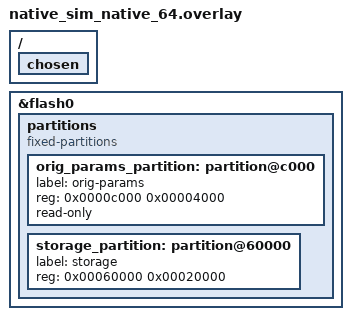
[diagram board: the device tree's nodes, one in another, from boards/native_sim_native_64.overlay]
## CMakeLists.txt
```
# SPDX-License-Identifier: Apache-2.0
# Wallfree-Anwendung fuer die Steuerung (nur bauen, nicht flashen) und fuer
# native_sim (Ende-zu-Ende-Test auf dem PC, docs/implementierung.md)
cmake_minimum_required(VERSION 3.20.0)
list(APPEND BOARD_ROOT ${CMAKE_CURRENT_SOURCE_DIR}/..)
list(APPEND ZEPHYR_EXTRA_MODULES ${CMAKE_CURRENT_SOURCE_DIR}/..)
# SOLL-BOOT-35: Anhang mit Laenge und CRC32 an zephyr.bin; nur dieses Abbild flashen
# (zephyr.hex/.elf haben ihn nicht, die Firmware verweigert dann das Laden). Vor
# find_package, weil Zephyr die Liste dort schon auswertet; fuer native_sim gibt es keine
# zephyr.bin, das Skript tut dann nichts.
set_property(GLOBAL APPEND PROPERTY extra_post_build_commands
  COMMAND python3 -I ${CMAKE_CURRENT_SOURCE_DIR}/../scripts/image-trailer.py --if-exists
  ${CMAKE_BINARY_DIR}/zephyr/zephyr.bin)
find_package(Zephyr REQUIRED HINTS $ENV{ZEPHYR_BASE})
project(wallfree)
# Wallfree-Patches am Zephyr-Baum (patches/zephyr, scripts/zephyr-patches.sh)
file(STRINGS ${ZEPHYR_BASE}/include/zephyr/net/http/server.h wf_ws_upgrade_cb REGEX "upgrade_cb;")
file(STRINGS ${ZEPHYR_BASE}/subsys/net/lib/sockets/sockets_inet.c wf_sock_leak REGEX "socket closed")
if(NOT wf_ws_upgrade_cb OR NOT wf_sock_leak)
  message(FATAL_ERROR "Zephyr-Patches fehlen (patches/zephyr): scripts/zephyr-patches.sh")
endif()
target_sources(app PRIVATE
  src/main.c
  src/evse_task.c
  src/protect_diag.c
  src/shell_evse.c
  src/shell_web.c
  src/log_ring.c
  src/storage.c
  src/auth.c
  src/http_api.c
  src/netcfg.c
  src/sysinfo.c
  src/meter_task.c
  src/mqtt_task.c
  src/history_task.c
  src/timesync.c
  src/resolve.c
)
if(CONFIG_ARCH_POSIX)
  # PC-Simulation (native_sim): Modell statt TIM1/ADC/GPIO, Neustart per execv
  target_sources(app PRIVATE src/hw_sim.c)
  target_sources(native_simulator INTERFACE ${CMAKE_CURRENT_SOURCE_DIR}/src/sim_host.c)
  target_include_directories(native_simulator INTERFACE ${CMAKE_CURRENT_SOURCE_DIR}/src)
else()
  target_sources(app PRIVATE src/hw_stm32.c src/hw_gpio.c src/meter_bus_modbus.c)
endif()
# Ressourcenliste des HTTP-Servers (HTTP_RESOURCE_DEFINE)
zephyr_linker_sources(SECTIONS sections-rom.ld)
zephyr_linker_section(NAME http_resource_desc_wallfree_http KVMA RAM_REGION GROUP RODATA_REGION)
# Weboberflaeche (SOLL-API-31): gzip-komprimiert im Flash
set(gen_dir ${ZEPHYR_BINARY_DIR}/include/generated/web)
foreach(f index.html app.js style.css vendor/preact-htm.js lizenzen.txt)
  get_filename_component(n ${f} NAME)
  generate_inc_file_for_target(app ${CMAKE_CURRENT_SOURCE_DIR}/../web/${f} ${gen_dir}/${n}.gz.inc --gzip)
endforeach()
zephyr_include_directories(${ZEPHYR_BINARY_DIR}/include/generated)
# Firmwarestand: Version aus VERSION (Major.Minor, Zwischenstaende "-dev"), Bauzeichen = Commit
# (Tags ausgeschlossen, bei Aenderungen "-dirty", ohne Git "unbekannt")
set_property(DIRECTORY APPEND PROPERTY CMAKE_CONFIGURE_DEPENDS ${CMAKE_CURRENT_SOURCE_DIR}/../VERSION)
file(STRINGS ${CMAKE_CURRENT_SOURCE_DIR}/../VERSION WALLFREE_VERSION LIMIT_COUNT 1)
execute_process(COMMAND git describe --always --dirty --exclude=*
  WORKING_DIRECTORY ${CMAKE_CURRENT_SOURCE_DIR}
  OUTPUT_VARIABLE WALLFREE_BUILD OUTPUT_STRIP_TRAILING_WHITESPACE ERROR_QUIET)
if(NOT WALLFREE_BUILD)
  set(WALLFREE_BUILD unbekannt)
endif()
target_compile_definitions(app PRIVATE WALLFREE_VERSION="${WALLFREE_VERSION}"
  WALLFREE_BUILD="${WALLFREE_BUILD}")
```

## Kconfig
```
# SPDX-License-Identifier: Apache-2.0
# Optionen der Wallfree-Anwendung

config WALLFREE_HTTP_PORT
	int "TCP-Port des HTTP-Servers"
	default 8081 if ARCH_POSIX
	default 80
	help
	  Auf der Steuerung 80. In der PC-Simulation (native_sim, Host-Sockets)
	  8081 (mit --http-port aenderbar), weil Ports unter 1024 dort Root-Rechte braeuchten.

config WALLFREE_TELNET_DEFAULT
	bool "Telnet-Shell ab Werk an"
	default y if ARCH_POSIX
	help
	  Werkswert von telnet_enable. Auf der Steuerung aus (F20). In der PC-Simulation an:
	  Dort ist die Shell die Bedienung des Hardwaremodells (Kommando sim).

source "Kconfig.zephyr"
```

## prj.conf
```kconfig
# SPDX-License-Identifier: Apache-2.0
# Wallfree-Anwendung. Hardwaretests nur im Rahmen der Freigaben in wallbe2/AGENTS.md.
CONFIG_WALLFREE_EVSE=y
CONFIG_MAIN_STACK_SIZE=2048
CONFIG_HEAP_MEM_POOL_SIZE=512
# kein CONFIG_REBOOT: Neustart nur geordnet ueber reboot (SOLL-RT-22), hw_reset()
CONFIG_REBOOT=n
CONFIG_WATCHDOG=y
CONFIG_GPIO=y
CONFIG_LOG=y
CONFIG_LOG_BACKEND_UART=n
# einziges Log-Backend der Steuerung: Ring im RAM, lesbar mit log (log_ring.c). Ohne
# Backend bricht Zephyrs Log-Thread beim Start mit einer Assertion ab (Startschleife)
CONFIG_LOG_OUTPUT=y
CONFIG_ASSERT=y
# Pruefungen bleiben; bei Ausloesung nur "ASSERTION FAIL @ Datei:Zeile" ohne
# Ausdruck und Meldungstext (spart 18 KB Flash, docs/architektur.md Abschnitt 5)
CONFIG_ASSERT_NO_COND_INFO=y
CONFIG_ASSERT_NO_MSG_INFO=y

# Netzwerk (IPv4, DHCP, TCP) ueber den Zephyr-Stack (F25: DHCP an)
CONFIG_NETWORKING=y
CONFIG_NET_IPV4=y
CONFIG_NET_IPV6=n
CONFIG_NET_TCP=y
CONFIG_NET_UDP=y
CONFIG_NET_DHCPV4=y
CONFIG_NET_SOCKETS=y
# Adresse und DHCP setzt die Anwendung (netcfg.c, net_dhcp/net_ip ...)
CONFIG_NET_CONFIG_AUTO_INIT=n
# 12: im Lasttest auf dem Testgeraet (Browser, 2 WebSockets, Abfrager, Telnet) 8..9 von 10 belegt, dazu
# MQTT und TIME_WAIT (Nutzer 2026-10-26)
CONFIG_NET_MAX_CONN=12
CONFIG_NET_MAX_CONTEXTS=12
CONFIG_ZVFS_OPEN_MAX=18
CONFIG_ZVFS_POLL_MAX=16
# eventfd: Socket-Service und HTTP-Server je einer. Mit 1 (Default) startet
# der HTTP-Server nicht ("eventfd failed (-12)", gefunden im PC-Test;
# ohne NET_LOG nicht im Log sichtbar)
CONFIG_ZVFS_EVENTFD_MAX=2
CONFIG_NET_HOSTNAME_ENABLE=y
CONFIG_NET_HOSTNAME="wallfree"
CONFIG_NET_HOSTNAME_DYNAMIC=y
CONFIG_NET_HOSTNAME_MAX_LEN=32
CONFIG_ETH_DRIVER=y
CONFIG_NET_L2_ETHERNET=y
# SOLL-RT-07: Netz-Threads unter Schutz- (0) und Automatenthread (2). Zephyr setzt sie sonst
# kooperativ (nicht unterbrechbar, ueber allen preemptiven Threads); auf dem Testgeraet liess
# HTTP-Dauerlast den Automatenthread > 50 ms warten -> supervision_limit. Mit dieser Option
# laufen auch HTTP-Server, net_mgmt und Ethernet-RX preemptiv (HTTP/net_mgmt niedrigste Prio).
CONFIG_NET_TC_THREAD_PREEMPTIVE=y
CONFIG_NET_TC_THREAD_PRIO_CUSTOM=y
CONFIG_NET_TC_RX_THREAD_BASE_PRIO=5
CONFIG_NET_TC_TX_THREAD_BASE_PRIO=5
CONFIG_NET_TCP_WORKER_PRIO=5
CONFIG_SYSTEM_WORKQUEUE_PRIORITY=5

# Shell nur ueber die Konsole der Weboberflaeche (SOLL-SH-19, shell_web.c): ein Kommando je
# Anfrage, ohne Telnet. Was nur eine interaktive Sitzung braucht, ist aus.
CONFIG_SHELL=y
CONFIG_SHELL_BACKEND_SERIAL=n
CONFIG_SHELL_BACKEND_TELNET=n
CONFIG_SHELL_LOG_BACKEND=n
CONFIG_SHELL_HISTORY=n
CONFIG_SHELL_TAB=n
CONFIG_SHELL_WILDCARD=n
CONFIG_SHELL_METAKEYS=n
CONFIG_SHELL_VT100_COMMANDS=n
CONFIG_SHELL_VT100_COLORS=n
CONFIG_SHELL_CMDS=n
CONFIG_SHELL_STATS=n
CONFIG_SHELL_PROMPT_CHANGE=n
# der Shell-Thread wartet nur, Kommandos laufen im HTTP-Server-Thread
CONFIG_SHELL_STACK_SIZE=1024
# SOLL-SH-21: keine Zephyr-Zusatzkommandos (kernel thread kill/suspend, devmem), Ersatz
# threads/uptime. Netz-Kommandos nach dem Lasttest entfernt, 17 KB (Nutzer 2026-10-26)
CONFIG_KERNEL_SHELL=n
CONFIG_DEVICE_SHELL=n
CONFIG_DEVMEM_SHELL=n
CONFIG_DATE_SHELL=n
CONFIG_NET_SHELL=n
# fuer threads (Stack-Auslastung)
CONFIG_INIT_STACKS=y
CONFIG_THREAD_MONITOR=y
CONFIG_THREAD_STACK_INFO=y
CONFIG_THREAD_NAME=y

# Parameterspeicher in Sektor 7 (SOLL-NVM-01), Sektor 3 nur lesen
CONFIG_WALLFREE_NVM=y
CONFIG_FLASH=y
CONFIG_FLASH_MAP=y

# HTTP-/WebSocket-API fuer evcc (Soll-Spezifikation 12.1), Digest-Anmeldung
CONFIG_WALLFREE_API=y
CONFIG_HTTP_PARSER=y
CONFIG_HTTP_PARSER_URL=y
CONFIG_HTTP_SERVER=y
CONFIG_HTTP_SERVER_VERSION_2=n
CONFIG_HTTP_SERVER_WEBSOCKET=y
# ein Kontext je WebSocket-Client (WS_MAX in http_api.c); Default 1 liess nur
# einen Client zu (gefunden im PC-Test)
CONFIG_WEBSOCKET_MAX_CONTEXTS=3
CONFIG_HTTP_SERVER_MAX_CLIENTS=4
# ruhende Verbindungen nach 5 s schliessen (Zephyr-Vorgabe 10 s); wie Apache, lighttpd und
# Node.js. Bei 4 Plaetzen haelt sonst eine vorab geoeffnete Browser-Verbindung lange einen
# (implementierung.md, Festlegung Verbindungsplaetze)
CONFIG_HTTP_SERVER_CLIENT_INACTIVITY_TIMEOUT=5
CONFIG_HTTP_SERVER_STACK_SIZE=4096
CONFIG_HTTP_SERVER_CLIENT_BUFFER_SIZE=512
CONFIG_HTTP_SERVER_MAX_HEADER_LEN=400
CONFIG_HTTP_SERVER_CAPTURE_HEADERS=y
CONFIG_HTTP_SERVER_CAPTURE_HEADER_COUNT=1
CONFIG_HTTP_SERVER_CAPTURE_HEADER_BUFFER_SIZE=420
CONFIG_ENTROPY_GENERATOR=y

# Uhrzeit per SNTP (SOLL-TIME-01..04): Zeitserver per Name (DNS nur auf der Steuerung,
# boards/ev_cc_ac1.conf) oder aus DHCP Option 42
CONFIG_SNTP=y

# MQTT-Client (Soll-Spezifikation 12.6, F30): 3.1.1 ueber TCP, ohne TLS
CONFIG_MQTT_LIB=y
CONFIG_MQTT_VERSION_3_1_1=y

# Energiezaehler, nur Anzeige (Soll-Spezifikation 12.5, F28); Modbus-Client
# nur auf der Steuerung (boards/ev_cc_ac1.conf), in der Simulation ein Modell
CONFIG_WALLFREE_METER=y
```

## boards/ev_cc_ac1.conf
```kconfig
# SPDX-License-Identifier: Apache-2.0
# Zaehlerbus auf UART4 (Soll-Spezifikation 12.5, F29): Modbus-Client von Zephyr
CONFIG_SERIAL=y
CONFIG_UART_INTERRUPT_DRIVEN=y
CONFIG_MODBUS=y
CONFIG_MODBUS_ROLE_CLIENT=y
CONFIG_MODBUS_FP_EXTENSIONS=n
# Eastron-Werkseinstellung 8N1 ist nach der Norm nicht zulaessig (SOLL-MTR-02)
CONFIG_MODBUS_NONCOMPLIANT_SERIAL_MODE=y
# Start ueber den Original-Bootloader: er laesst SysTick, USART2, RTC und NVIC-Freigaben
# eingeschaltet; ohne Ruecksetzen kam ein Fehler vor main (Testgeraet, 2026-10-24)
CONFIG_INIT_ARCH_HW_AT_BOOT=y
# SOLL-RT-07: Ethernet-RX preemptiv (Folge von NET_TC_THREAD_PREEMPTIVE) unter dem
# Automatenthread (2), ueber den Netz-Threads (5)
CONFIG_ETH_STM32_HAL_RX_THREAD_PRIO=4
# SNTP: Zeitserver per Name, asynchron ohne Heap (timesync.c)
CONFIG_DNS_RESOLVER=y
CONFIG_DNS_RESOLVER_MAX_SERVERS=2
CONFIG_DNS_NUM_CONCUR_QUERIES=1
```

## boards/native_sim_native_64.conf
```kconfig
# SPDX-License-Identifier: Apache-2.0
# PC-Simulation (native_sim): Hardware durch Modell ersetzt (hw_sim.c),
# Netz ueber Host-Sockets (kein TAP, keine Root-Rechte), Flash-Simulator
# mit Datei (--flash=<datei>). Rein fuer Tests auf dem PC.
CONFIG_SYS_CLOCK_TICKS_PER_SEC=10000
CONFIG_WATCHDOG=n
CONFIG_ETH_DRIVER=n
CONFIG_NET_L2_ETHERNET=n
CONFIG_ETH_NATIVE_TAP=n
CONFIG_NET_DRIVERS=y
CONFIG_NET_SOCKETS_OFFLOAD=y
CONFIG_NET_NATIVE_OFFLOADED_SOCKETS=y
CONFIG_NET_DHCPV4=n
# Telnet nur hier: Testzugang ohne Anmeldung fuer das Hardwaremodell (Kommando sim) und die
# Tests, auf der Steuerung nicht vorhanden (SOLL-SH-19)
CONFIG_SHELL_BACKEND_TELNET=y
CONFIG_SHELL_TELNET_PORT=2323
CONFIG_SHELL_TELNET_SUPPORT_COMMAND=y
CONFIG_SHELL_HISTORY=y
CONFIG_SHELL_TAB=y
CONFIG_SHELL_METAKEYS=y
CONFIG_SHELL_VT100_COMMANDS=y
CONFIG_SHELL_STACK_SIZE=2048
# Log auf die Konsole (stdout)
CONFIG_LOG_BACKEND_NATIVE_POSIX=y
CONFIG_FLASH_SIMULATOR=y
CONFIG_ENTROPY_GENERATOR=y
CONFIG_NET_LOG=y
# Logging wie auf der Steuerung (native_sim waehlt sonst den Sofortmodus)
CONFIG_LOG_MODE_DEFERRED=y
CONFIG_LOG_MODE_IMMEDIATE=n
# Ruhende HTTP-Verbindungen werden hier nie getrennt (NSOS ohne shutdown, siehe
# docs/implementierung.md); ein Browser haelt bis zu 6. Mehr Plaetze als auf der
# Steuerung (4), damit evcc daneben erreichbar bleibt.
CONFIG_HTTP_SERVER_MAX_CLIENTS=8
CONFIG_ZVFS_OPEN_MAX=24
```

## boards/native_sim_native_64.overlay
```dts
/* SPDX-License-Identifier: Apache-2.0 */
/*
 * PC-Simulation: Flash-Partitionen an denselben Stellen wie auf der
 * Steuerung (Sektor 3 Originalparameter, Sektor 7 Wallfree-Parameter),
 * damit storage.c unveraendert bleibt.
 */
/delete-node/ &boot_partition;
/delete-node/ &slot0_partition;
/delete-node/ &slot1_partition;
/delete-node/ &scratch_partition;
/delete-node/ &storage_partition;

&flash0 {
	partitions {
		compatible = "fixed-partitions";
		#address-cells = <1>;
		#size-cells = <1>;

		orig_params_partition: partition@c000 {
			label = "orig-params";
			reg = <0x0000c000 0x00004000>;
			read-only;
		};
		storage_partition: partition@60000 {
			label = "storage";
			reg = <0x00060000 0x00020000>;
		};
	};
};

/ {
	chosen {
		/delete-property/ zephyr,code-partition;
	};
};
```

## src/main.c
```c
/* SPDX-License-Identifier: Apache-2.0 */
/*
 * Wallfree: Ersatzfirmware fuer EV-CC-AC1-M3-CBC-RCM-ETH.
 * Startablauf nach Soll-Spezifikation Abschnitt 13.2.
 */
#include <zephyr/kernel.h>
#include <zephyr/logging/log.h>
#include <wallfree/evse/charger.h>
#include "evse_task.h"
#include "history_task.h"
#include "http_api.h"
#include "hw.h"
#include "meter_task.h"
#include "mqtt_task.h"
#include "netcfg.h"
#include "storage.h"
#include "sysinfo.h"
#include "timesync.h"

LOG_MODULE_REGISTER(main, LOG_LEVEL_INF);

#define BOOTLOADER_MS    5000  /* SOLL-BOOT-22: Loslassen ab hier -> Bootloader */
#define FACTORY_RESET_MS 10000 /* SOLL-BOOT-20 */
/* Schalter: PA11/PA12 haben nur den internen Pull-up; nach dem Einschalten braucht der
 * Pegel einige ms (Testgeraet las D8 sonst als an). Erst warten, dann stabil lesen. */
#define SWITCH_SETTLE_MS 20
#define SWITCH_STEP_MS   10
#define SWITCH_STABLE    3  /* gleiche Lesungen in Folge */
#define SWITCH_MAX_READS 30
#define BLINK_5HZ_MS     100  /* halbe Periode */
#define BLINK_1HZ_MS     500  /* halbe Periode */

enum button_action {
	BUTTON_NONE,
	BUTTON_BOOTLOADER,
	BUTTON_FACTORY_RESET,
};

/* SOLL-BOOT-20/22: Reset-Taster beim Start gehalten. Losgelassen vor 5 s -> normaler
 * Start, zwischen 5 und 10 s -> Bootloader, 10 s gehalten -> Werkseinstellungen.
 * Waehrend des Wartens wird der IWDG bedient (Schuetz ist aus); die Power-LED blinkt
 * erst mit 1 Hz, ab 5 s mit 5 Hz (SOLL-LED-01), sonst wirkt die Steuerung aus. */
static enum button_action check_reset_button(void)
{
	if (!hw_gpio_reset_button()) {
		return BUTTON_NONE;
	}
	int64_t t0 = k_uptime_get(), dt = 0;

	while (hw_gpio_reset_button()) {
		dt = k_uptime_get() - t0;
		evse_task_wdt_feed();
		hw_gpio_led(EVSE_LED_POWER, dt < BOOTLOADER_MS ? (dt / BLINK_1HZ_MS) % 2 == 0
							     : (dt / BLINK_5HZ_MS) % 2 == 0);
		if (dt >= FACTORY_RESET_MS) {
			return BUTTON_FACTORY_RESET;
		}
		k_msleep(10);
	}
	hw_gpio_led(EVSE_LED_POWER, false);
	return dt >= BOOTLOADER_MS ? BUTTON_BOOTLOADER : BUTTON_NONE;
}

/* SOLL-BOOT-06/SOLL-IO-30: einmal beim Start, aber erst wenn der Wert stabil ist */
static void read_switches_stable(evse_dip_t *dip, uint8_t *rotary)
{
	evse_dip_t d, last_d = 0;
	uint8_t r, last_r = 0;
	int same = 0;

	k_msleep(SWITCH_SETTLE_MS);
	for (int i = 0; i < SWITCH_MAX_READS && same < SWITCH_STABLE; i++) {
		evse_task_wdt_feed();
		hw_gpio_read_switches(&d, &r);
		same = (i > 0 && d == last_d && r == last_r) ? same + 1 : 1;
		last_d = d;
		last_r = r;
		k_msleep(SWITCH_STEP_MS);
	}
	if (same < SWITCH_STABLE) {
		LOG_WRN("Schalter nicht stabil, letzter Wert gilt");
	}
	*dip = last_d;
	*rotary = last_r;
}

/* SOLL-BOOT-20, SOLL-LED-01: nach dem Werksreset Power-LED an bis zum Loslassen */
static void light_until_released(void)
{
	hw_gpio_led(EVSE_LED_POWER, true);
	while (hw_gpio_reset_button()) {
		evse_task_wdt_feed();
		k_msleep(10);
	}
	hw_gpio_led(EVSE_LED_POWER, false);
}

int main(void)
{
	struct evse_config cfg;
	enum evse_lock_state lock = EVSE_LOCK_UNLOCKED;
	evse_dip_t dip;
	uint8_t rotary;

	sysinfo_init(); /* SOLL-RT-14: Resetgrund vor allem anderen sichern */
	if (hw_gpio_init() != 0) {
		/* ohne GPIO kein sicherer Betrieb: Ausgaenge bleiben im Startpegel */
		hw_safe_state_regs();
		return -1;
	}
	/* SOLL-BOOT-03: IWDG sofort; bis zum Schutzthread bedient main ihn */
	if (evse_task_wdt_start() != 0) {
		LOG_ERR("IWDG nicht verfuegbar");
		hw_safe_state_regs();
		return -1;
	}

	/* SOLL-BOOT-04/05: Parameterspeicher; Loeschen ist hier erlaubt (Ladelogik
	 * noch nicht gestartet, Ausgaenge im sicheren Startpegel) */
	(void)storage_init();
	evse_task_wdt_feed();
	switch (check_reset_button()) {
	case BUTTON_FACTORY_RESET:
		LOG_WRN("Werksreset: Parameterbereich wird geloescht");
		(void)storage_factory_reset_boot(); /* IWDG dabei verlaengert */
		light_until_released();
		break;
	case BUTTON_BOOTLOADER:
		/* SOLL-BOOT-22: Ladelogik nicht gestartet; ohne Adresse nimmt der Bootloader
		 * seine feste 192.168.0.8 */
		LOG_WRN("Reset-Taster: Uebergabe an den Bootloader (192.168.0.8)");
		for (int i = 0; i < 20; i++) { /* 200 ms fuer das Log, IWDG weiter bedienen */
			evse_task_wdt_feed();
			k_msleep(10);
		}
		hw_bootloader_handover(0, 0);
	default:
		break;
	}
	evse_config_defaults(&cfg);
	(void)storage_load(&cfg, &lock);
	evse_task_wdt_feed();

	/* SOLL-BOOT-06: DIP und Drehschalter nur beim Start lesen */
	read_switches_stable(&dip, &rotary);
	cfg.dip = dip;
	cfg.rotary = rotary;
	LOG_INF("DIP 0x%03x, Drehschalter %u", dip, rotary);

	hw_analog_init();                  /* SOLL-BOOT-07 */
	int r = evse_task_start(&cfg, lock); /* SOLL-BOOT-08..10 */
	uint8_t upd_mode;
	bool upd_ok;

	uint32_t img_crc;

	if (sysinfo_image(&img_crc) == 0) {
		/* SOLL-BOOT-35: ungueltiges Abbild -> Klasse P, kein Laden bis zum naechsten Start */
		evse_acquire()->errors |= EVSE_ERR_INTERNAL;
		evse_release();
	}
	unsigned int fault;
	uint32_t pc;
	enum wf_reset_detail det = sysinfo_reset_detail(&fault, &pc);

	/* SOLL-ERR-12: jeder Start steht mit Grund im Protokoll, das Neustarts uebersteht */
	evse_task_event_push((struct wf_event){.t = k_uptime_get(), .type = WF_EV_BOOT,
					       .a = sysinfo_reset_reason(), .b = det,
					       .set = pc, .cleared = fault});
	if (sysinfo_update_result(&upd_mode, &upd_ok)) {
		/* SOLL-BOOT-33 */
		evse_task_event_push((struct wf_event){
			.t = k_uptime_get(), .type = WF_EV_UPDATE, .a = upd_ok, .b = upd_mode});
	}

	storage_start();
	netcfg_init();          /* Hostname, DHCP bzw. feste Adresse */
	(void)http_api_start(); /* SOLL-BOOT-09: Netz verzoegert den Ladeablauf nicht */

	struct wf_sysconf sys;

	netcfg_get(&sys, NULL);
	meter_task_start(&sys); /* SOLL-MTR-01: ohne Zaehler nichts */
	mqtt_task_start();      /* SOLL-MQTT-01: ohne mqtt_enable keine Verbindung */
	history_task_start();   /* SOLL-API-33 */
	timesync_start();       /* SOLL-TIME-01: ohne Zeitserver nichts */
	return r;
}
```

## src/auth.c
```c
/* SPDX-License-Identifier: Apache-2.0 */
/* Zugangsdaten fuer Web/API, siehe auth.h. Nur gebaut. */
#include <string.h>
#include <zephyr/kernel.h>
#include <zephyr/logging/log.h>
#include <zephyr/random/random.h>
#include "auth.h"
#include "storage.h"

LOG_MODULE_REGISTER(auth, LOG_LEVEL_INF);

static char user[WF_DIGEST_USER_MAX + 1];
static struct wf_digest_cfg cfg;
static bool factory_credentials;

void auth_init(void)
{
	uint8_t rec[16 + WF_DIGEST_USER_MAX];
	int n = storage_read_raw(STORAGE_ID_WEB_CRED, rec, sizeof(rec));

	cfg.realm = WF_DIGEST_REALM;
	cfg.user = user;
	if (n > 16) {
		memcpy(cfg.ha1, rec, 16);
		memcpy(user, rec + 16, (size_t)n - 16);
		user[n - 16] = '\0';
		factory_credentials = false;
	} else {
		strcpy(user, AUTH_DEFAULT_USER);
		wf_digest_ha1(AUTH_DEFAULT_USER, WF_DIGEST_REALM, AUTH_DEFAULT_PASSWORD, cfg.ha1);
		factory_credentials = true;
		LOG_WRN("Werkszugang aktiv: Passwortaenderung erforderlich");
	}
	/* Nonces gelten nur bis zum naechsten Start */
	if (sys_csrand_get(cfg.secret, sizeof(cfg.secret)) != 0) {
		sys_rand_get(cfg.secret, sizeof(cfg.secret));
	}
}

enum wf_auth auth_check(const char *hdr, const char *method, const char *uri)
{
	return wf_digest_check(&cfg, hdr, method, uri);
}

int auth_challenge(bool stale, char *out, size_t size)
{
	return wf_digest_challenge(&cfg, k_uptime_get_32(), stale, out, size);
}

const char *auth_user(void)
{
	return user;
}

bool auth_must_change(void)
{
	return factory_credentials;
}

const char *auth_change(const char *new_user, const char *password)
{
	size_t ul = strlen(new_user);
	size_t pl = strlen(password);

	if (ul == 0 || ul > WF_DIGEST_USER_MAX) {
		return "Benutzername: 1..32 Zeichen";
	}
	for (size_t i = 0; i < ul; i++) {
		char c = new_user[i];

		if (c < 0x21 || c > 0x7E || c == '"' || c == ':' || c == '\\') {
			return "Benutzername: nur druckbare Zeichen ohne Leerzeichen, '\"', ':', '\\'";
		}
	}
	if (pl < AUTH_PW_MIN || pl > AUTH_PW_MAX) {
		return "Passwort: 8..64 Zeichen";
	}
	if (strcmp(password, AUTH_DEFAULT_PASSWORD) == 0) {
		return "Passwort darf nicht das Werkspasswort sein";
	}
	uint8_t rec[16 + WF_DIGEST_USER_MAX];

	wf_digest_ha1(new_user, WF_DIGEST_REALM, password, rec);
	memcpy(rec + 16, new_user, ul);
	/* ein Eintrag: Benutzer und HA1 aendern sich nur gemeinsam */
	if (storage_save_raw(STORAGE_ID_WEB_CRED, rec, 16 + ul) < 0) {
		return "Speichern fehlgeschlagen";
	}
	memcpy(user, new_user, ul + 1);
	memcpy(cfg.ha1, rec, 16);
	factory_credentials = false;
	LOG_INF("Zugangsdaten geaendert");
	return NULL;
}
```

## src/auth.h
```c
/* SPDX-License-Identifier: Apache-2.0 */
/*
 * Zugangsdaten fuer Web/API (SOLL-API-07, F20): HTTP-Digest MD5, gespeichert
 * wird nur HA1. Werkszustand: Benutzer "admin", Passwort "wallfree"; bis zur
 * Aenderung beantwortet die API nur POST /credentials.
 * Alle Funktionen laufen im Thread des HTTP-Servers.
 */
#ifndef WALLFREE_APP_AUTH_H_
#define WALLFREE_APP_AUTH_H_

#include <stdbool.h>
#include <stddef.h>
#include <wallfree/api/digest.h>

#define AUTH_DEFAULT_USER     "admin"
#define AUTH_DEFAULT_PASSWORD "wallfree"
#define AUTH_PW_MIN 8
#define AUTH_PW_MAX 64

/** Gespeicherte Zugangsdaten laden, Nonce-Geheimnis wuerfeln. */
void auth_init(void);

enum wf_auth auth_check(const char *hdr, const char *method, const char *uri);

/** WWW-Authenticate-Wert. @return Laenge oder -1 */
int auth_challenge(bool stale, char *out, size_t size);

/** Aktueller Benutzername (fuer GET /credentials). */
const char *auth_user(void);

/** Werkszugang aktiv: Passwortaenderung erzwingen. */
bool auth_must_change(void);

/**
 * Zugangsdaten aendern (Benutzer 1..32 druckbare Zeichen ohne '"', ':', '\\';
 * Passwort 8..64 Zeichen, nicht das Werkspasswort).
 * @return NULL bei Erfolg, sonst Klartext des Fehlers
 */
const char *auth_change(const char *user, const char *password);

#endif
```

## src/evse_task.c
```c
/* SPDX-License-Identifier: Apache-2.0 */
/*
 * Ablaufeinheiten (Soll-Spezifikation Abschnitt 3):
 *  - Schutzthread (hoechste Thread-Prioritaet, 1 ms): RCM-Pegel zyklisch
 *    pruefen, Threads ueberwachen, IWDG bedienen (SOLL-RT-10..12,
 *    SOLL-PROT-05 Rueckfallebene).
 *  - Automatenthread (10 ms und bei jedem Messblock): evse_step(),
 *    Ausgaben setzen.
 *  - Fault-Handler: sicherer Zustand per Register, dann Neustart (SOLL-RT-21).
 *
 * Nur gebaut, auf Hardware nicht ausgefuehrt.
 */
#include <zephyr/fatal.h>
#include <zephyr/kernel.h>
#include <zephyr/logging/log.h>
#include <zephyr/logging/log_ctrl.h>
#include <zephyr/sys/atomic.h>
#include <wallfree/api/events.h>
#include "evse_task.h"
#include "http_api.h"
#include "hw.h"
#include "storage.h"

LOG_MODULE_REGISTER(evse_task, LOG_LEVEL_INF);

static atomic_t want_on; /* Soll des Automaten fuer das Schuetz, fuer die Meldung */

#define PROT_PRIO      0   /* hoechste preemptive Prioritaet */
#define CHARGER_PRIO   2
#define PROT_STACK     1024
#define CHARGER_STACK  2048

#define CHARGER_CYCLE_MS 10   /* SOLL-RT-05 */
#define LIMIT_CHARGER_MS 100  /* SOLL-RT-10 (F4) */
#define LIMIT_BLOCK_MS   50
#define IWDG_TIMEOUT_MS  250  /* SOLL-RT-12 */
#define STARTUP_GRACE_MS 1000

static struct evse ev;
static K_MUTEX_DEFINE(ev_mtx);

static atomic_t charger_beat;   /* Zeitstempel ms (untere 32 Bit) */
static atomic_t block_beat;
static atomic_t started;
static atomic_t maint;          /* Ueberwachung ausgesetzt (Flash-Loeschen) */

K_THREAD_STACK_DEFINE(prot_stack, PROT_STACK);
K_THREAD_STACK_DEFINE(charger_stack, CHARGER_STACK);
static struct k_thread prot_thread;
static struct k_thread charger_thread;

struct evse *evse_acquire(void)
{
	k_mutex_lock(&ev_mtx, K_FOREVER);
	return &ev;
}

void evse_release(void)
{
	k_mutex_unlock(&ev_mtx);
}

/* ------------------------------------------------ geordneter Neustart (SOLL-RT-22) */

#define REBOOT_WAIT_MS 15000

static int64_t reboot_deadline;
static atomic_t reboot_pending;
static enum wf_reset reboot_code;
static bool handover;           /* statt Reset an den Bootloader (SOLL-BOOT-30) */
static uint32_t handover_ip, handover_mask;

static void reboot_work_fn(struct k_work *w);
static K_WORK_DELAYABLE_DEFINE(reboot_work, reboot_work_fn);

/*
 * Kein LOG_PANIC: ein Shell-Log-Backend (frueher Telnet) bricht dabei seine Sende-Arbeit
 * mit k_work_cancel_delayable_sync() auf der Systemworkqueue ab, in der dieser Ablauf
 * selbst laeuft (Selbstblockade, gefunden im PC-Test). Stattdessen bekommt der
 * Log-Thread nach der Meldung REBOOT_LOG_MS zum Ausgeben.
 */
#define REBOOT_LOG_MS 200

static bool reboot_logged;

static void reboot_work_fn(struct k_work *w)
{
	ARG_UNUSED(w);
	if (reboot_logged) {
		/* beide zuerst sicherer Zustand */
		if (handover) {
			hw_bootloader_handover(handover_ip, handover_mask);
		}
		hw_reset_with(reboot_code);
	}
	struct evse *e = evse_acquire();
	bool off = evse_contactor_is_off(e);

	evse_release();
	if (off || k_uptime_get() >= reboot_deadline) {
		if (!off) {
			/* Schuetz sofort aus, nicht erst nach der Log-Wartezeit */
			hw_safe_state_regs();
		}
		LOG_WRN("%s%s", handover ? "Uebergabe an den Bootloader" : "Neustart",
			off ? "" : " nach Fristablauf (Schuetz hart abgeschaltet)");
		reboot_logged = true;
		k_work_schedule(&reboot_work, K_MSEC(REBOOT_LOG_MS));
		return;
	}
	k_work_schedule(&reboot_work, K_MSEC(100));
}

static int orderly(enum wf_reset code, bool to_bootloader, uint32_t ip, uint32_t mask)
{
	if (!atomic_cas(&reboot_pending, 0, 1)) {
		return -EALREADY;
	}
	reboot_code = code;
	handover = to_bootloader;
	handover_ip = ip;
	handover_mask = mask;
	evse_request_shutdown(evse_acquire());
	evse_release();
	reboot_deadline = k_uptime_get() + REBOOT_WAIT_MS;
	/* kurz warten, damit Antworten (HTTP, Shell) noch hinausgehen */
	k_work_schedule(&reboot_work, K_MSEC(300));
	return 0;
}

int evse_task_reboot_orderly(enum wf_reset code)
{
	return orderly(code, false, 0, 0);
}

int evse_task_update_orderly(uint32_t ip, uint32_t mask)
{
	return orderly(WF_RST_UPDATE, true, ip, mask);
}

void evse_task_maint_begin(void)
{
	atomic_set(&maint, 1);
}

void evse_task_maint_end(void)
{
	int64_t now = k_uptime_get();

	atomic_set(&charger_beat, (atomic_val_t)now);
	atomic_set(&block_beat, (atomic_val_t)now);
	atomic_set(&maint, 0);
}

/* ------------------------------------------------ sicherer Zustand und Neustart */

static void fail_safe_and_reboot(const char *why, enum wf_reset_detail detail)
{
	hw_safe_state_regs();
	hw_reset_detail(detail); /* SOLL-RT-14: welche Ueberwachung, steht nach dem Start im Protokoll */
	/* ohne LOG_PANIC (siehe reboot_work_fn); die Meldung geht evtl. verloren,
	 * der Grund steht im Backup-Register (SOLL-RT-14) */
	LOG_ERR("sicherer Zustand: %s", why);
	hw_reset_with(WF_RST_LIMIT);
}

void k_sys_fatal_error_handler(unsigned int reason, const struct arch_esf *esf)
{
	/* SOLL-RT-21: zuerst Schuetz aus und CP -12 V, dann Neustart */
	hw_safe_state_regs();
#ifdef CONFIG_ARM
	hw_fault_note(reason, esf != NULL ? esf->basic.pc : 0);
#else
	ARG_UNUSED(esf);
	hw_fault_note(reason, 0);
#endif
	LOG_PANIC();
	LOG_ERR("Fataler Fehler %u, Neustart", reason);
	hw_reset_with(WF_RST_FAULT);
}

/* ------------------------------------------------ Ereignisse (SOLL-ERR-10) */

static struct wf_ev_ring ev_ring;
static struct k_spinlock ev_lock;

static void events_post(const struct wf_ev_snap *before, const struct wf_ev_snap *after,
			int64_t now)
{
	struct wf_event ev[WF_EV_MAX_DIFF];
	size_t n = wf_ev_diff(before, after, now, ev);

	if (n == 0) {
		return;
	}
	k_spinlock_key_t key = k_spin_lock(&ev_lock);

	for (size_t i = 0; i < n; i++) {
		wf_ev_ring_push(&ev_ring, ev[i]);
	}
	k_spin_unlock(&ev_lock, key);
	http_api_notify(); /* Ausgabe und Log im WebSocket-Thread */
}

void evse_task_event_push(struct wf_event ev)
{
	k_spinlock_key_t key = k_spin_lock(&ev_lock);

	wf_ev_ring_push(&ev_ring, ev);
	k_spin_unlock(&ev_lock, key);
	http_api_notify();
}

bool evse_task_event_get(uint32_t *seq, struct wf_event *ev)
{
	k_spinlock_key_t key = k_spin_lock(&ev_lock);
	bool ok = wf_ev_ring_get(&ev_ring, seq, ev);

	k_spin_unlock(&ev_lock, key);
	return ok;
}

/* ------------------------------------------------ Automatenthread */

static void charger_entry(void *p1, void *p2, void *p3)
{
	ARG_UNUSED(p1);
	ARG_UNUSED(p2);
	ARG_UNUSED(p3);
	uint32_t last_seq = 0;
	enum evse_lock_state last_lock = EVSE_LOCK_INIT;

	for (;;) {
		struct evse_inputs in = {0};
		struct hw_block blk;
		struct evse_outputs out;

		(void)k_sem_take(&hw_block_sem, K_MSEC(CHARGER_CYCLE_MS));
		int64_t now = k_uptime_get();

		if (hw_get_block(&blk) && blk.seq != last_seq) {
			last_seq = blk.seq;
			in.new_block = true;
			atomic_set(&block_beat, (atomic_val_t)blk.at_ms);
		}
		in.cp_pos_mv = blk.cp_pos;
		in.cp_neg_mv = blk.cp_neg;
		in.pp_mv = blk.pp;
		for (int i = 0; i < EVSE_DIN_COUNT; i++) {
			in.din_mv[i] = blk.din[i];
		}
		in.supply_mv = blk.supply;
		hw_gpio_read_rcm(&in.rcm);
		in.protect_tripped = hw_protect_latched(); /* SOLL-PROT-14 */
		in.last_sense_edge = hw_gpio_last_sense_edge();
		in.meter_valid = false; /* keine Messquelle (F1) */

		struct wf_ev_snap snap_before, snap_after;

		k_mutex_lock(&ev_mtx, K_FOREVER);
		wf_ev_snap_take(&ev, &snap_before);
		evse_step(&ev, &in, now);
		wf_ev_snap_take(&ev, &snap_after);
		out = ev.out;
		bool p_errors = (ev.errors & EVSE_ERR_CLASS_P) != 0;
		enum evse_lock_state lock = ev.lock.state;
		k_mutex_unlock(&ev_mtx);

		events_post(&snap_before, &snap_after, now);

		/* Feld 465: Endzustand speichern lassen (Speicher-Thread, SOLL-PAR-40) */
		if (lock != last_lock) {
			last_lock = lock;
			storage_lock_changed(lock);
		}

		/* Schutz-Latch des ISR-Pfads erst loesen, wenn die Ladelogik den
		 * Fehler uebernommen hat bzw. keine Ausloesung mehr ansteht */
		if (hw_protect_latched() && !p_errors && !in.rcm.sw1 && !in.rcm.sw2 && !in.rcm.err &&
		    !out.contactor) {
			hw_protect_clear();
		}

		atomic_set(&want_on, out.contactor);
		hw_cp_set_duty(out.cp_duty);
		hw_gpio_apply(&out);
		atomic_set(&charger_beat, (atomic_val_t)now);
	}
}

/* ------------------------------------------------ Schutzpfad: Logmeldung (SOLL-PROT-15) */

static const char *const prot_line_name[HW_PROT_LINES] = {"SWITCH_1", "SWITCH_2", "ERR_OUT"};

/* Jede neue Ausloesung des Schutzmerkers einmal melden (Schutzthread, 1 ms) */
static void protect_log(void)
{
	static bool was;
	bool now = hw_protect_latched();

	if (now && !was) {
		struct hw_protect_diag d;

		hw_protect_diag(&d);
		/* bei Schuetz aus meist der Selbsttest (Testimpuls), bei Schuetz ein ein Befund */
		const char *ctx = atomic_get(&want_on) ? "Schuetz soll ein" : "Schuetz soll aus";

		if (d.last_line >= 0) {
			LOG_WRN("Schutzpfad ausgeloest: %s ueber %s (%s)", prot_line_name[d.last_line],
				d.last_path == HW_PROT_POLL ? "zyklische Kontrolle" : "Interrupt", ctx);
		} else {
			LOG_WRN("Schutzpfad ausgeloest (%s)", ctx);
		}
	}
	was = now;
}

/* ------------------------------------------------ IWDG (SOLL-BOOT-03, SOLL-RT-12) */

static atomic_t wdt_ok;

int evse_task_wdt_start(void)
{
	int r = hw_wdt_start(IWDG_TIMEOUT_MS);

	atomic_set(&wdt_ok, r == 0);
	return r;
}

void evse_task_wdt_feed(void)
{
	/* nur bis der Schutzthread laeuft; danach bedient ausschliesslich er */
	if (atomic_get(&wdt_ok) && !atomic_get(&started)) {
		hw_wdt_feed();
	}
}

/* ------------------------------------------------ Schnittstellen-Threads (SOLL-RT-11) */

#define IFACE_LIMIT_MS 10000

static atomic_t iface_beat[EVSE_IFACE_COUNT];
static const char *const iface_names[EVSE_IFACE_COUNT] = {"storage", "ws_push", "sysworkq",
								  "http_server"};
static const enum wf_reset_detail iface_detail[EVSE_IFACE_COUNT] = {
	WF_RSTD_IFACE_STORAGE, WF_RSTD_IFACE_WS, WF_RSTD_IFACE_SYSWORKQ, WF_RSTD_IFACE_HTTP};
static atomic_t http_busy; /* HTTP-Server steckt in einem Aufruf der Anwendung */

void evse_task_iface_beat(enum evse_iface id)
{
	atomic_set(&iface_beat[id], (atomic_val_t)k_uptime_get_32());
}

/* HTTP-Server: meldet sich nicht zyklisch; ueberwacht wird die Dauer jedes Aufrufs */
void evse_task_http_busy(bool busy)
{
	if (busy) {
		evse_task_iface_beat(EVSE_IFACE_HTTP);
	}
	atomic_set(&http_busy, busy);
}

static void sysworkq_beat_fn(struct k_work *w);
static K_WORK_DELAYABLE_DEFINE(sysworkq_beat, sysworkq_beat_fn);

static void sysworkq_beat_fn(struct k_work *w)
{
	ARG_UNUSED(w);
	evse_task_iface_beat(EVSE_IFACE_SYSWORKQ);
	k_work_schedule(&sysworkq_beat, K_SECONDS(1));
}

/*
 * Einmal je Sekunde aus dem Schutzthread: haengt ein Schnittstellen-Thread
 * laenger als 10 s, Meldung; Neustart nur ohne Ladevorgang (Schuetz aus,
 * S1/S9/S10). Die Sperre der Ladelogik wird nur ohne Warten versucht.
 */
static void check_ifaces(uint32_t now32)
{
	static bool reported;
	int hung = -1;

	for (int i = 0; i < EVSE_IFACE_COUNT; i++) {
		if (i == EVSE_IFACE_HTTP && !atomic_get(&http_busy)) {
			continue;
		}
		if (now32 - (uint32_t)atomic_get(&iface_beat[i]) > IFACE_LIMIT_MS) {
			hung = i;
		}
	}
	if (hung < 0) {
		reported = false;
		return;
	}
	if (!reported) {
		reported = true;
		LOG_ERR("Thread %s meldet sich nicht (> %d s)", iface_names[hung], IFACE_LIMIT_MS / 1000);
	}
	if (k_mutex_lock(&ev_mtx, K_NO_WAIT) != 0) {
		return;
	}
	bool idle = evse_contactor_is_off(&ev) &&
		    (ev.state == EVSE_S1_IDLE || ev.state == EVSE_S9_ERROR ||
		     ev.state == EVSE_S10_UNAVAILABLE);

	k_mutex_unlock(&ev_mtx);
	if (idle) {
		hw_reset_detail(iface_detail[hung]);
		hw_reset_with(WF_RST_NET_HANG);
	}
}

/* ------------------------------------------------ Schutzthread */

static void prot_entry(void *p1, void *p2, void *p3)
{
	ARG_UNUSED(p1);
	ARG_UNUSED(p2);
	ARG_UNUSED(p3);
	if (!atomic_get(&wdt_ok)) {
		fail_safe_and_reboot("IWDG nicht verfuegbar", WF_RSTD_NONE);
	}
	int64_t t0 = k_uptime_get();
	int64_t last_iface_check = t0;
	bool prev_act[HW_PROT_LINES] = {false};

	for (;;) {
		struct evse_rcm_levels lv;
		int64_t now = k_uptime_get();
		uint32_t now32 = (uint32_t)now;

		/* SOLL-PROT-05 Rueckfallebene: zyklische Pegelkontrolle, zwei Messungen in Folge
		 * (Stoerfilter, F35) */
		hw_gpio_read_rcm(&lv);
		bool act[HW_PROT_LINES] = {lv.sw1, lv.sw2, lv.err};

		for (int l = 0; l < HW_PROT_LINES; l++) {
			if (act[l] && prev_act[l]) {
				if (!hw_protect_latched()) {
					hw_protect_note((enum hw_prot_line)l, HW_PROT_POLL);
				}
				hw_protect_trip();
			}
			prev_act[l] = act[l];
		}
		protect_log();

		/* SOLL-RT-10: Thread- und Messueberwachung */
		if (now - t0 > STARTUP_GRACE_MS && !atomic_get(&maint)) {
			if (now32 - (uint32_t)atomic_get(&charger_beat) > LIMIT_CHARGER_MS) {
				fail_safe_and_reboot("Automatenthread haengt", WF_RSTD_CHARGER);
			}
			if (now32 - (uint32_t)atomic_get(&block_beat) > LIMIT_BLOCK_MS) {
				fail_safe_and_reboot("keine Messbloecke", WF_RSTD_BLOCKS);
			}
		}
		/* SOLL-RT-11: Schnittstellen-Threads, einmal je Sekunde */
		if (now - t0 > STARTUP_GRACE_MS && now - last_iface_check >= 1000) {
			last_iface_check = now;
			check_ifaces(now32);
		}
		/* SOLL-RT-12: IWDG nur bei eingehaltenen Limits */
		hw_wdt_feed();
		k_sleep(K_MSEC(1));
	}
}

int evse_task_start(const struct evse_config *cfg, enum evse_lock_state stored_lock)
{
	if (atomic_cas(&started, 0, 1) == false) {
		return -EALREADY;
	}
	int64_t now = k_uptime_get();

	evse_init(&ev, cfg, stored_lock, now);
	wf_ev_ring_init(&ev_ring);
	atomic_set(&charger_beat, (atomic_val_t)now);
	atomic_set(&block_beat, (atomic_val_t)now);
	for (int i = 0; i < EVSE_IFACE_COUNT; i++) {
		evse_task_iface_beat(i);
	}
	k_work_schedule(&sysworkq_beat, K_SECONDS(1));

	k_thread_create(&prot_thread, prot_stack, K_THREAD_STACK_SIZEOF(prot_stack), prot_entry,
			NULL, NULL, NULL, PROT_PRIO, 0, K_NO_WAIT);
	k_thread_name_set(&prot_thread, "evse_prot");
	k_thread_create(&charger_thread, charger_stack, K_THREAD_STACK_SIZEOF(charger_stack),
			charger_entry, NULL, NULL, NULL, CHARGER_PRIO, 0, K_NO_WAIT);
	k_thread_name_set(&charger_thread, "evse_logic");
	return 0;
}
```

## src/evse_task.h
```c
/* SPDX-License-Identifier: Apache-2.0 */
#ifndef WALLFREE_APP_EVSE_TASK_H_
#define WALLFREE_APP_EVSE_TASK_H_

#include <wallfree/api/events.h>
#include <wallfree/api/reset.h>
#include <wallfree/evse/charger.h>

/**
 * Ladelogik und Schutzpfad starten (SOLL-BOOT-07..10).
 * @param stored_lock gespeicherter Verriegelungszustand (Feld 465)
 */
int evse_task_start(const struct evse_config *cfg, enum evse_lock_state stored_lock);

/**
 * Zugriff auf die Ladelogik fuer Schnittstellen (SOLL-API-20/21): kurze,
 * begrenzte Sperre; nie blockierend fuer den Schutzpfad.
 */
struct evse *evse_acquire(void);
void evse_release(void);

/**
 * Wartung (Flash-Loeschen, SOLL-NVM-04/SOLL-RT-13): Thread- und
 * Messueberwachung aussetzen. Nur mit gehaltener evse_acquire()-Sperre im
 * sicheren Zustand verwenden; danach gelten die Limits wieder ab jetzt.
 */
/**
 * Geordneter Neustart (SOLL-RT-22, SOLL-SH-11): Ladeende anfordern, auf
 * Schuetz aus warten (hoechstens 15 s), sicherer Zustand, Reset. Kehrt sofort
 * zurueck. @return 0 oder -EALREADY
 */
int evse_task_reboot_orderly(enum wf_reset code);

/**
 * Update-Uebergabe (SOLL-BOOT-30): wie der geordnete Neustart, am Ende aber an den
 * Bootloader mit @p ip / @p mask (netcfg_ipv4). Kehrt sofort zurueck.
 * @return 0 oder -EALREADY
 */
int evse_task_update_orderly(uint32_t ip, uint32_t mask);

/** IWDG gleich zu Beginn von main starten (SOLL-BOOT-03). @return 0 oder Fehler */
int evse_task_wdt_start(void);

/** IWDG bedienen, solange der Schutzthread noch nicht laeuft (Startablauf). */
void evse_task_wdt_feed(void);

/** Ueberwachte Schnittstellen-Threads (SOLL-RT-11) */
enum evse_iface {
	EVSE_IFACE_STORAGE = 0,
	EVSE_IFACE_WS,
	EVSE_IFACE_SYSWORKQ,
	EVSE_IFACE_HTTP, /* meldet Beginn und Ende jedes Aufrufs (evse_task_http_busy) */
	EVSE_IFACE_COUNT,
};

/** Lebenszeichen eines Schnittstellen-Threads (Limit 10 s). */
void evse_task_iface_beat(enum evse_iface id);

/** HTTP-Server betritt (true) bzw. verlaesst einen Aufruf der Anwendung (Limit 10 s je Aufruf). */
void evse_task_http_busy(bool busy);

/**
 * Naechstes Ereignis (SOLL-ERR-10) ab Nummer @p *seq, siehe wf_ev_ring_get.
 * Erkannt im Automatenthread, ausgegeben im WebSocket-Thread.
 */
bool evse_task_event_get(uint32_t *seq, struct wf_event *ev);

/** Ereignis aus einem anderen Thread einreihen (Zaehler, SOLL-MTR-14); seq vergibt der Puffer. */
void evse_task_event_push(struct wf_event ev);

void evse_task_maint_begin(void);
void evse_task_maint_end(void);

#endif
```

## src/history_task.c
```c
/* SPDX-License-Identifier: Apache-2.0 */
/* Verlauf (SOLL-API-33) */
#include <zephyr/kernel.h>
#include <wallfree/api/evse_api.h>
#include <wallfree/api/history.h>
#include <wallfree/evse/charger.h>
#include "evse_task.h"
#include "history_task.h"
#include "meter_task.h"

#define SAMPLE_MS 1000

static struct wf_hist hist;
static K_MUTEX_DEFINE(hist_mtx);

static void sample_fn(struct k_work *w);
static K_WORK_DELAYABLE_DEFINE(sample_work, sample_fn);

static void sample_fn(struct k_work *w)
{
	ARG_UNUSED(w);
	static struct meter_values mv; /* nicht auf dem Stack der Systemworkqueue */
	int32_t power = -1;
	uint8_t flags = 0;
	struct evse *e = evse_acquire();
	int iec = api_iec61851_state(e);
	int cs = api_charger_state(e);
	int32_t allowed = evse_allowed_current(e);

	if (api_error_state(e) != 0 || cs == 4) {
		flags |= WF_HIST_ERROR;
	}
	evse_release();
	if (iec >= 1 && iec <= 3) {
		flags |= WF_HIST_CONNECTED;
	}
	if (cs == 3) {
		flags |= WF_HIST_CHARGING;
	}
	if (meter_task_type() != METER_NONE) {
		(void)meter_task_get(&mv);
		if (mv.valid[METER_P]) {
			/* mW; Einspeisung an der Ladestation zaehlt als 0 */
			power = mv.v[METER_P] > 0 ? (int32_t)(mv.v[METER_P] / 1000) : 0;
		}
	}
	k_mutex_lock(&hist_mtx, K_FOREVER);
	wf_hist_add(&hist, k_uptime_get(), power, allowed, flags);
	k_mutex_unlock(&hist_mtx);
	k_work_schedule(&sample_work, K_MSEC(SAMPLE_MS));
}

void history_task_start(void)
{
	wf_hist_init(&hist);
	k_work_schedule(&sample_work, K_NO_WAIT);
}

uint32_t history_task_json(uint32_t cursor, struct wf_jbuf *b)
{
	k_mutex_lock(&hist_mtx, K_FOREVER);
	uint32_t next = wf_hist_json(&hist, k_uptime_get(), cursor, b);

	k_mutex_unlock(&hist_mtx);
	return next;
}
```

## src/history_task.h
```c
/* SPDX-License-Identifier: Apache-2.0 */
/*
 * Verlauf (SOLL-API-33): Abtastung je Sekunde auf der Systemworkqueue,
 * Ringpuffer nur im RAM.
 */
#ifndef WALLFREE_APP_HISTORY_TASK_H_
#define WALLFREE_APP_HISTORY_TASK_H_

#include <stdint.h>
#include <wallfree/api/json.h>

void history_task_start(void);

/** wie wf_hist_json, mit Sperre */
uint32_t history_task_json(uint32_t cursor, struct wf_jbuf *b);

#endif
```

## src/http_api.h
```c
/* SPDX-License-Identifier: Apache-2.0 */
#ifndef WALLFREE_APP_HTTP_API_H_
#define WALLFREE_APP_HTTP_API_H_

/** Zugangsdaten laden, WebSocket-Thread und HTTP-Server (Port 80) starten. */
int http_api_start(void);

/** WebSocket-Thread wecken (neue Ereignisse oder geaenderte Werte). */
void http_api_notify(void);

/** Uhrzeit fuer das Protokoll: ms seit 1970 bei Laufzeit 0, 0 = unbekannt (SNTP) */
void http_api_set_wall_base(int64_t wall_base);

#endif
```

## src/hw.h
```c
/* SPDX-License-Identifier: Apache-2.0 */
/*
 * Hardwareschicht der Steuerung EV-CC-AC1-M3-CBC-RCM-ETH.
 * Pinbelegung und Skalierung: Firmwarebefunde des Originals (wallbe2,
 * docs/takt-adc-gpio.md), keine Schaltplanbestaetigung. Nur gebaut, auf
 * Hardware nicht ausgefuehrt und nicht freigegeben.
 */
#ifndef WALLFREE_APP_HW_H_
#define WALLFREE_APP_HW_H_

#include <zephyr/kernel.h>
#include <zephyr/linker/section_tags.h>
#include <wallfree/api/reset.h>
#include <wallfree/evse/charger.h>

/** Ein Messblock: Mittel ueber 8 PWM-Perioden, Skalierung wie Original ("mV"). */
struct hw_block {
	int32_t cp_pos;
	int32_t cp_neg;
	int32_t pp;
	int32_t din[EVSE_DIN_COUNT];
	int32_t supply;
	int32_t temp_raw;  /**< Summe Rang 10 im Block mit Temperatursensor */
	int32_t vref_raw;  /**< Summe Rang 10 im Block mit interner Referenz, 0 = noch keiner */
	uint32_t seq;
	int64_t at_ms;
};

/* ---- hw_stm32.c: TIM1, ADC1, DMA2, MCO1, sicherer Zustand ---- */

/** CP-PWM und Messung starten (SOLL-RT-01..03). */
int hw_analog_init(void);

/** Tastgrad in Promille (0 = -12 V, 1000 = +12 V). */
void hw_cp_set_duty(uint16_t permille);

/** Letzten Messblock kopieren. @return false, wenn noch keiner vorliegt. */
bool hw_get_block(struct hw_block *out);

/**
 * Chiptemperatur der MCU in 0,1 Grad C aus dem letzten Messblock (Sensor ADC1_IN16, typische
 * Kennwerte des Datenblatts, keine Kalibrierung; Streuung zwischen Chips laut RM0033 bis 45 Grad,
 * also fuer Aenderungen brauchbar, nicht als Absolutwert). @return 0 oder -EAGAIN ohne Messblock
 */
int hw_mcu_temp(int32_t *dc);

/**
 * Referenzspannung VREF+ des ADC in mV, berechnet aus der internen Referenz (VREFINT, typisch
 * 1,21 V, Streuung +-2,5 %). Nur zur Kontrolle der in der Skalierung angenommenen 2,495 V.
 * @return 0 oder -EAGAIN ohne Messung
 */
int hw_adc_vref(int32_t *mv);

/** Wird bei jedem neuen Messblock gegeben. */
extern struct k_sem hw_block_sem;

/**
 * Sicherer Zustand ueber direkte Registerzugriffe, auch aus Fault-Handlern
 * (SOLL-RT-20/21): Schuetz aus, CP -12 V, Aktor in Ruhe, kein RCM-Test.
 */
void hw_safe_state_regs(void);

/** Schuetz sofort aus (Registerzugriff, ISR-tauglich). */
void hw_contactor_off_regs(void);

/**
 * Systemreset mit Grund (SOLL-RT-14): sicherer Zustand, Code in RTC-Backup-
 * Register 19, Reset. Ohne Zephyr-REBOOT, damit 'kernel reboot' entfaellt.
 */
FUNC_NORETURN void hw_reset_with(enum wf_reset code);

/**
 * Fehlerort einer Prozessorausnahme: Programmzaehler in Backup-Register 17, Detail
 * WF_RSTD_FAULT mit Ausnahmegrund in Register 18 (SOLL-RT-14).
 */
void hw_fault_note(unsigned int reason, uint32_t pc);

/** Genauerer Ausloeser vor einem Software-Reset (Backup-Register 18, SOLL-RT-14). */
void hw_reset_detail(enum wf_reset_detail d);

/**
 * Beim Start: Reset-Flags (RCC_CSR), Code aus Backup-Register 19, Detail aus 18 und
 * Programmzaehler aus 17 lesen und loeschen. @p flags als WF_RSTF_*.
 */
void hw_reset_take(uint32_t *flags, uint32_t *bkp, uint32_t *detail, uint32_t *pc);

/**
 * RTC lesen (SOLL-TIME-04): Takt und Kalender hat der Bootloader eingerichtet, kein
 * Zephyr-Treiber. @return Unix-Sekunden oder 0 (nicht gueltig, nie gestellt, Takt fehlt)
 */
uint64_t hw_rtc_read_s(void);

/** RTC stellen (UTC); @p s in WF_NTP_*_EPOCH. Haelt die Zaehler kurz an, nur aus Threads. */
void hw_rtc_write_s(uint64_t s);

/*
 * CP-Aufnahme (SOLL-API-34): aequivalente Abtastung des CP-Signals mit ADC2, ohne die
 * Messung der Ladelogik (ADC1) zu beruehren. Je PWM-Periode ein Abtastpunkt beim
 * Abwaertszaehlen von TIM1 (CC2), Phase von Periode zu Periode verschoben; die Plateaumitten,
 * in denen ADC1 misst, bleiben ausgespart. Die PWM ist zentriert-symmetrisch: Die Punkte
 * decken die zweite Periodenhaelfte ab, die erste ist ihr Spiegelbild (t -> 1000 - t).
 */
#define HW_SCOPE_N     111 /**< Punkte, t = HW_SCOPE_T0_US - i * HW_SCOPE_DT_US */
#define HW_SCOPE_T0_US 970
#define HW_SCOPE_DT_US 4

struct hw_scope {
	uint16_t duty;               /**< Tastgrad in Promille waehrend der Aufnahme */
	int16_t pos_mv[HW_SCOPE_N];  /**< Kanal CP+ (wie cp_pos skaliert) */
	int16_t neg_mv[HW_SCOPE_N];  /**< Kanal CP-, Betrag (wie cp_neg skaliert) */
};

/** Aufnahme (blockiert etwa 120 ms, nicht aus ISR). @return 0, -EBUSY oder -ETIMEDOUT */
int hw_cp_scope(struct hw_scope *out);

/*
 * Speicher, der einen Reset uebersteht (Backup-SRAM 4 KB, SOLL-ERR-12), aber keinen
 * Stromausfall (keine Batterie an VBAT bekannt): Variablen mit HW_RETAINED anlegen, beim
 * Start hw_retained_attach() aufrufen und den Inhalt selbst auf Stimmigkeit pruefen.
 * In der Simulation reicht ein Neustart (execv) den Inhalt ueber die Umgebung weiter.
 */
#ifdef CONFIG_ARCH_POSIX
#define HW_RETAINED
#else
#define HW_RETAINED __stm32_backup_sram_section
#endif
void hw_retained_attach(void *p, size_t len);

/**
 * Beim Start: Fehlerbits in FLASH_SR lesen und loeschen. Der Zephyr-Treiber laesst
 * sonst den ersten Schreibzugriff mit -EIO scheitern, wenn beim Start ein Fehlerbit
 * stehen blieb (Testgeraet 2026-10-24, Herkunft offen). @return vorgefundene Fehlerbits
 */
uint32_t hw_flash_take_errors(void);

/** Fehlerbits in FLASH_SR, gelesen vor allen Treibern (Diagnose der Herkunft). */
uint32_t hw_flash_errors_early(void);

/**
 * Uebergabe an den Original-Bootloader (SOLL-BOOT-30/31): sicherer Zustand, BKP10 = 2
 * (Web-Update), BKP11 = 3 Versuche, BKP15 = 0, BKP13/14 = IP und Maske in lwIP-Byteordnung
 * (0 = Bootloader nimmt 192.168.0.8), Resetgrund "update" in BKP19, Systemreset.
 */
FUNC_NORETURN void hw_bootloader_handover(uint32_t ip, uint32_t mask);

/** Beim Start: BKP12 (Ergebnis eines Updates, SOLL-BOOT-33) lesen und loeschen. */
uint32_t hw_update_result_take(void);

/**
 * SOLL-BOOT-35: CRC32 ueber das eigene Abbild (Laenge _flash_used) und Vergleich mit dem
 * Anhang des Builds. @return 1 gueltig, 0 Anhang fehlt oder CRC falsch, -1 nicht pruefbar
 * (Simulation)
 */
int hw_image_check(uint32_t *crc);

/**
 * SOLL-SH-24: len Byte ab addr aus Flash, OTP oder Optionsbytes kopieren (nur lesend). Der
 * Bereich muss vorher mit wf_flashread_check() geprueft sein.
 * @return 0 oder -ENOTSUP (Simulation)
 */
int hw_flash_read(uint32_t addr, uint8_t *buf, uint32_t len);

#define HW_BOOT_REGS 8
/**
 * Diagnose, vor hw_reset_take() und hw_update_result_take(): RCC_CSR roh, dann BKP10..16 des
 * Bootloaders (Modus, Versuche, Ergebnis, IP, Maske, SIM, Zaehler der IWDG-Starts).
 */
void hw_boot_regs(uint32_t out[HW_BOOT_REGS]);

/**
 * Geraete-MAC aus dem OTP-Bereich (ab 0x1FFF7800, vom Hersteller gesetzt, Spezifikation 10.1).
 * @return false, wenn keine gueltige Einzeladresse hinterlegt ist (dann bleibt die erzeugte)
 */
bool hw_device_mac(uint8_t mac[6]);

/** IWDG starten (SOLL-BOOT-03). @return 0 oder Fehler */
int hw_wdt_start(uint32_t timeout_ms);

/** IWDG bedienen. */
void hw_wdt_feed(void);

/**
 * IWDG-Limit fuer Flash-Loeschen auf das Maximum setzen (true) bzw. den
 * vorherigen Wert wiederherstellen (false), SOLL-RT-13.
 */
void hw_iwdg_long(bool on);

/* ---- hw_gpio.c: digitale Ein-/Ausgaenge, Schutz-Interrupts ---- */

int hw_gpio_init(void);
void hw_gpio_read_switches(evse_dip_t *dip, uint8_t *rotary);
bool hw_gpio_reset_button(void);
/** Einzelne LED direkt setzen (nur vor dem Start der Ladelogik, z. B. Werksreset). */
void hw_gpio_led(enum evse_led led, bool on);
void hw_gpio_read_rcm(struct evse_rcm_levels *lv);
/** Netzwerk-LED PC2 [HYP] (SOLL-LED-06), unabhaengig von der Ladelogik. */
void hw_gpio_net_led(bool on);
int64_t hw_gpio_last_sense_edge(void);

/**
 * Ausgaenge setzen. Das Schuetz wird nur eingeschaltet, wenn kein
 * Schutz-Latch des ISR-Pfads ansteht (SOLL-PROT-01).
 */
void hw_gpio_apply(const struct evse_outputs *o);

/** Schutz-Latch: gesetzt durch RCM-Interrupt bzw. Schutzthread. */
bool hw_protect_latched(void);
void hw_protect_trip(void);
void hw_protect_clear(void);

/* ---- protect_diag.c: Diagnose des Schutzpfads (SOLL-PROT-15) ---- */

enum hw_prot_line { HW_PROT_SW1, HW_PROT_SW2, HW_PROT_ERR, HW_PROT_LINES };
enum hw_prot_path {
	HW_PROT_ISR,         /**< Interrupt, Pegel bestaetigt: ausgeloest */
	HW_PROT_ISR_IGNORED, /**< Interrupt, Pegel schon wieder weg: verworfen (Stoerfilter) */
	HW_PROT_POLL,        /**< zyklische Kontrolle, zwei Messungen: ausgeloest */
	HW_PROT_PATHS
};

struct hw_protect_diag {
	uint32_t count[HW_PROT_PATHS][HW_PROT_LINES];
	int last_line;   /**< letzte Ausloesung, -1 = keine */
	int last_path;
	int64_t last_ms; /**< Laufzeit der letzten Ausloesung */
};

void hw_protect_note(enum hw_prot_line line, enum hw_prot_path path);
void hw_protect_diag(struct hw_protect_diag *d);

#if defined(CONFIG_ARCH_POSIX)
/** PC-Simulation: HTTP-Port aus der Kommandozeile (--http-port). */
uint16_t hw_sim_http_port(void);
/** PC-Simulation: Netzverbindung laut Modell ("sim link"). */
bool hw_sim_link(void);
#endif

#endif /* WALLFREE_APP_HW_H_ */
```
